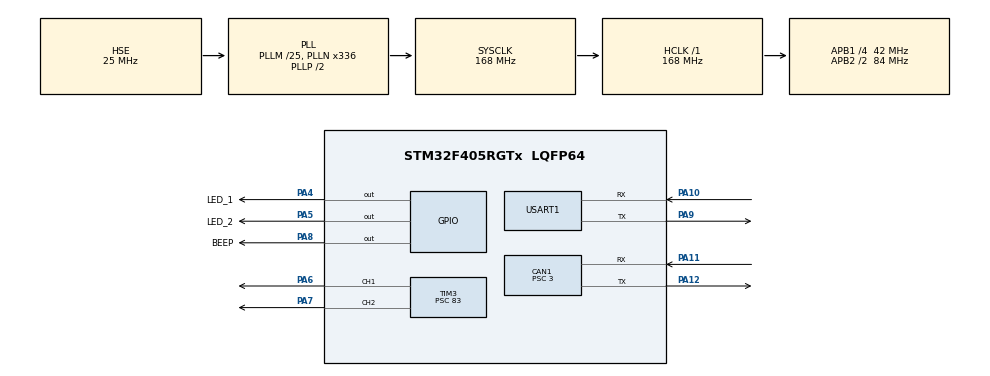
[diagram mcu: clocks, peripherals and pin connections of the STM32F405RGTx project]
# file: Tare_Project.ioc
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CAN1.ABOM=ENABLE
CAN1.AWUM=ENABLE
CAN1.BS1=CAN_BS1_9TQ
CAN1.BS2=CAN_BS2_4TQ
CAN1.CalculateBaudRate=1000000
CAN1.CalculateTimeBit=1000
CAN1.CalculateTimeQuantum=71.42857142857143
CAN1.NART=ENABLE
CAN1.Prescaler=3
Dma.Request0=USART1_RX
Dma.Request1=USART1_TX
Dma.USART1_RX.0.Direction=DMA_PERIPH_TO_MEMORY
Dma.USART1_RX.0.FIFOMode=DMA_FIFOMODE_DISABLE
Dma.USART1_RX.0.Instance=DMA2_Stream2
Dma.USART1_RX.0.MemDataAlignment=DMA_MDATAALIGN_BYTE
Dma.USART1_RX.0.MemInc=DMA_MINC_ENABLE
Dma.USART1_RX.0.Mode=DMA_NORMAL
Dma.USART1_RX.0.PeriphDataAlignment=DMA_PDATAALIGN_BYTE
Dma.USART1_RX.0.PeriphInc=DMA_PINC_DISABLE
Dma.USART1_RX.0.Priority=DMA_PRIORITY_LOW
Dma.USART1_TX.1.Direction=DMA_MEMORY_TO_PERIPH
Dma.USART1_TX.1.FIFOMode=DMA_FIFOMODE_DISABLE
Dma.USART1_TX.1.Instance=DMA2_Stream7
Dma.USART1_TX.1.MemDataAlignment=DMA_MDATAALIGN_BYTE
Dma.USART1_TX.1.MemInc=DMA_MINC_ENABLE
Dma.USART1_TX.1.Mode=DMA_NORMAL
Dma.USART1_TX.1.PeriphDataAlignment=DMA_PDATAALIGN_BYTE
Dma.USART1_TX.1.PeriphInc=DMA_PINC_DISABLE
Dma.USART1_TX.1.Priority=DMA_PRIORITY_LOW
FREERTOS.Tasks01=defaultTask,24,128,StartDefaultTask,Default,NULL,Dynamic,NULL,NULL;LEDTASK,8,128,Breath_LED,As weak,NULL,Dynamic,NULL,NULL;UARTTask,8,128,Data_update,As weak,NULL,Dynamic,NULL,NULL;FLOATTASK,8,128,Receivefloat,As weak,NULL,Dynamic,NULL,NULL;BEERTASK,8,128,Beep,As weak,NULL,Dynamic,NULL,NULL;NoiseTASK,8,128,Noise,As weak,NULL,Dynamic,NULL,NULL
Mcu.Family=STM32F4
Mcu.Name=STM32F405RGTx
Mcu.Package=LQFP64
NVIC.CAN1_RX0_IRQn=true\:5\:0\:false\:false\:true\:true\:true\:true\:true
NVIC.CAN1_RX1_IRQn=true\:5\:0\:false\:false\:true\:true\:true\:true\:true
NVIC.DMA2_Stream2_IRQn=true\:5\:0\:false\:false\:true\:true\:false\:true\:true
NVIC.DMA2_Stream7_IRQn=true\:5\:0\:false\:false\:true\:true\:false\:true\:true
NVIC.PriorityGroup=NVIC_PRIORITYGROUP_4
NVIC.TIM1_UP_TIM10_IRQn=true\:15\:0\:false\:false\:true\:false\:false\:true\:true
NVIC.TIM2_IRQn=true\:5\:0\:false\:false\:true\:true\:true\:true\:true
NVIC.TIM3_IRQn=true\:5\:0\:false\:false\:true\:true\:true\:true\:true
NVIC.TimeBase=TIM1_UP_TIM10_IRQn
NVIC.TimeBaseIP=TIM1
NVIC.USART1_IRQn=true\:5\:0\:false\:false\:true\:true\:false\:true\:true
PA10.Mode=Asynchronous
PA10.Signal=USART1_RX
PA11.Mode=CAN_Activate
PA11.Signal=CAN1_RX
PA12.GPIO_PuPd=GPIO_PULLDOWN
PA12.Mode=CAN_Activate
PA12.Signal=CAN1_TX
PA13.Mode=Serial_Wire
PA13.Signal=SYS_JTMS-SWDIO
PA14.Mode=Serial_Wire
PA14.Signal=SYS_JTCK-SWCLK
PA4.GPIO_Label=LED_1
PA4.GPIO_PuPd=GPIO_PULLDOWN
PA4.Signal=GPIO_Output
PA5.GPIO_Label=LED_2
PA5.GPIO_PuPd=GPIO_PULLDOWN
PA5.Signal=GPIO_Output
PA6.Signal=S_TIM3_CH1
PA7.Signal=S_TIM3_CH2
PA8.GPIO_Label=BEEP
PA8.GPIO_PuPd=GPIO_PULLDOWN
PA8.Signal=GPIO_Output
PA9.Mode=Asynchronous
PA9.Signal=USART1_TX
PC14-OSC32_IN.Mode=LSE-External-Oscillator
PC14-OSC32_IN.Signal=RCC_OSC32_IN
PC15-OSC32_OUT.Mode=LSE-External-Oscillator
PC15-OSC32_OUT.Signal=RCC_OSC32_OUT
PH0-OSC_IN.Mode=HSE-External-Oscillator
PH0-OSC_IN.Signal=RCC_OSC_IN
PH1-OSC_OUT.Mode=HSE-External-Oscillator
PH1-OSC_OUT.Signal=RCC_OSC_OUT
ProjectManager.HeapSize=0x200
ProjectManager.StackSize=0x400
ProjectManager.TargetToolchain=MDK-ARM V5.32
RCC.48MHZClocksFreq_Value=84000000
RCC.AHBFreq_Value=168000000
RCC.APB1CLKDivider=RCC_HCLK_DIV4
RCC.APB1Freq_Value=42000000
RCC.APB1TimFreq_Value=84000000
RCC.APB2CLKDivider=RCC_HCLK_DIV2
RCC.APB2Freq_Value=84000000
RCC.APB2TimFreq_Value=168000000
RCC.CortexFreq_Value=168000000
RCC.HCLKFreq_Value=168000000
RCC.HSE_VALUE=25000000
RCC.HSI_VALUE=16000000
RCC.PLLM=25
RCC.PLLN=336
RCC.PLLSourceVirtual=RCC_PLLSOURCE_HSE
RCC.SYSCLKFreq_VALUE=168000000
RCC.SYSCLKSource=RCC_SYSCLKSOURCE_PLLCLK
RCC.VCOOutputFreq_Value=336000000
SH.S_TIM3_CH1.0=TIM3_CH1,PWM Generation1 CH1
SH.S_TIM3_CH2.0=TIM3_CH2,PWM Generation2 CH2
TIM2.Period=1999
TIM2.Prescaler=83
TIM3.Channel-PWM\ Generation1\ CH1=TIM_CHANNEL_1
TIM3.Channel-PWM\ Generation2\ CH2=TIM_CHANNEL_2
TIM3.Period=999
TIM3.Prescaler=83
USART1.VirtualMode=VM_ASYNC
VP_FREERTOS_VS_CMSIS_V2.Mode=CMSIS_V2
VP_SYS_VS_tim1.Mode=TIM1
VP_TIM2_VS_ClockSourceINT.Mode=Internal
VP_TIM3_VS_ClockSourceINT.Mode=Internal
board=custom

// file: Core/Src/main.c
/* USER CODE BEGIN Header */
/**
  ******************************************************************************
  * @file           : main.c
  * @brief          : Main program body
  ******************************************************************************
  * @attention
  *
  * Copyright (c) 2026 STMicroelectronics.
  * All rights reserved.
  *
  * This software is licensed under terms that can be found in the LICENSE file
  * in the root directory of this software component.
  * If no LICENSE file comes with this software, it is provided AS-IS.
  *
  ******************************************************************************
  */
/* USER CODE END Header */
#include "main.h"
#include "cmsis_os.h"
#include "can.h"
#include "dma.h"
#include "tim.h"
#include "usart.h"
#include "gpio.h"
#include "UART_IQRhandler.h"
#include "led.h"

void SystemClock_Config(void);
void MX_FREERTOS_Init(void);

int main(void)
{

  /* MCU Configuration--------------------------------------------------------*/

  /* Reset of all peripherals, Initializes the Flash interface and the Systick. */
  HAL_Init();

  /* Configure the system clock */
  SystemClock_Config();

  /* Initialize all configured peripherals */
  MX_GPIO_Init();
  MX_DMA_Init();
  MX_TIM2_Init();
  MX_TIM3_Init();
  MX_USART1_UART_Init();
  MX_CAN1_Init();
  /* USER CODE BEGIN 2 */
  UART_Start_Receive();
  HAL_TIM_PWM_Start(&htim3,TIM_CHANNEL_1);
  HAL_TIM_PWM_Start(&htim3,TIM_CHANNEL_2);
  /* USER CODE END 2 */

  /* Init scheduler */
  osKernelInitialize();  /* Call init function for freertos objects (in cmsis_os2.c) */
  MX_FREERTOS_Init();

  /* Start scheduler */
  osKernelStart();

  /* We should never get here as control is now taken by the scheduler */

  /* Infinite loop */
  while (1)
  {

  }
}

void SystemClock_Config(void)
{
  RCC_OscInitTypeDef RCC_OscInitStruct = {0};
  RCC_ClkInitTypeDef RCC_ClkInitStruct = {0};

  /** Configure the main internal regulator output voltage
  */
  __HAL_RCC_PWR_CLK_ENABLE();
  __HAL_PWR_VOLTAGESCALING_CONFIG(PWR_REGULATOR_VOLTAGE_SCALE1);

  /** Initializes the RCC Oscillators according to the specified parameters
  * in the RCC_OscInitTypeDef structure.
  */
  RCC_OscInitStruct.OscillatorType = RCC_OSCILLATORTYPE_HSE;
  RCC_OscInitStruct.HSEState = RCC_HSE_ON;
  RCC_OscInitStruct.PLL.PLLState = RCC_PLL_ON;
  RCC_OscInitStruct.PLL.PLLSource = RCC_PLLSOURCE_HSE;
  RCC_OscInitStruct.PLL.PLLM = 25;
  RCC_OscInitStruct.PLL.PLLN = 336;
  RCC_OscInitStruct.PLL.PLLP = RCC_PLLP_DIV2;
  RCC_OscInitStruct.PLL.PLLQ = 4;
  if (HAL_RCC_OscConfig(&RCC_OscInitStruct) != HAL_OK)
  {
    Error_Handler();
  }

  /** Initializes the CPU, AHB and APB buses clocks
  */
  RCC_ClkInitStruct.ClockType = RCC_CLOCKTYPE_HCLK|RCC_CLOCKTYPE_SYSCLK
                              |RCC_CLOCKTYPE_PCLK1|RCC_CLOCKTYPE_PCLK2;
  RCC_ClkInitStruct.SYSCLKSource = RCC_SYSCLKSOURCE_PLLCLK;
  RCC_ClkInitStruct.AHBCLKDivider = RCC_SYSCLK_DIV1;
  RCC_ClkInitStruct.APB1CLKDivider = RCC_HCLK_DIV4;
  RCC_ClkInitStruct.APB2CLKDivider = RCC_HCLK_DIV2;

  if (HAL_RCC_ClockConfig(&RCC_ClkInitStruct, FLASH_LATENCY_5) != HAL_OK)
  {
    Error_Handler();
  }
}

void HAL_TIM_PeriodElapsedCallback(TIM_HandleTypeDef *htim)
{
  if (htim->Instance == TIM1)
  {
    HAL_IncTick();
	  ledflow();
  }
}

void Error_Handler(void)
{
  __disable_irq();
  while (1)
  {
  }
}

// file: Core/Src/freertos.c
/* USER CODE BEGIN Header */
/**
  ******************************************************************************
  * File Name          : freertos.c
  * Description        : Code for freertos applications
  ******************************************************************************
  * @attention
  *
  * Copyright (c) 2026 STMicroelectronics.
  * All rights reserved.
  *
  * This software is licensed under terms that can be found in the LICENSE file
  * in the root directory of this software component.
  * If no LICENSE file comes with this software, it is provided AS-IS.
  *
  ******************************************************************************
  */
/* USER CODE END Header */

#include "FreeRTOS.h"
#include "task.h"
#include "main.h"
#include "cmsis_os.h"

/* Definitions for defaultTask */
osThreadId_t defaultTaskHandle;
const osThreadAttr_t defaultTask_attributes = {
  .name = "defaultTask",
  .stack_size = 128 * 4,
  .priority = (osPriority_t) osPriorityNormal,
};
/* Definitions for LEDTASK */
osThreadId_t LEDTASKHandle;
const osThreadAttr_t LEDTASK_attributes = {
  .name = "LEDTASK",
  .stack_size = 128 * 4,
  .priority = (osPriority_t) osPriorityLow,
};
/* Definitions for UARTTask */
osThreadId_t UARTTaskHandle;
const osThreadAttr_t UARTTask_attributes = {
  .name = "UARTTask",
  .stack_size = 128 * 4,
  .priority = (osPriority_t) osPriorityLow,
};
/* Definitions for FLOATTASK */
osThreadId_t FLOATTASKHandle;
const osThreadAttr_t FLOATTASK_attributes = {
  .name = "FLOATTASK",
  .stack_size = 128 * 4,
  .priority = (osPriority_t) osPriorityLow,
};
/* Definitions for BEERTASK */
osThreadId_t BEERTASKHandle;
const osThreadAttr_t BEERTASK_attributes = {
  .name = "BEERTASK",
  .stack_size = 128 * 4,
  .priority = (osPriority_t) osPriorityLow,
};
/* Definitions for NoiseTASK */
osThreadId_t NoiseTASKHandle;
const osThreadAttr_t NoiseTASK_attributes = {
  .name = "NoiseTASK",
  .stack_size = 128 * 4,
  .priority = (osPriority_t) osPriorityLow,
};

void StartDefaultTask(void *argument);
void Breath_LED(void *argument);
void Data_update(void *argument);
void Receivefloat(void *argument);
void Beep(void *argument);
void Noise(void *argument);

void MX_FREERTOS_Init(void); /* (MISRA C 2004 rule 8.1) */

void MX_FREERTOS_Init(void) {

  /* Create the thread(s) */
  /* creation of defaultTask */
  defaultTaskHandle = osThreadNew(StartDefaultTask, NULL, &defaultTask_attributes);

  /* creation of LEDTASK */
  LEDTASKHandle = osThreadNew(Breath_LED, NULL, &LEDTASK_attributes);

  /* creation of UARTTask */
  UARTTaskHandle = osThreadNew(Data_update, NULL, &UARTTask_attributes);

  /* creation of FLOATTASK */
  FLOATTASKHandle = osThreadNew(Receivefloat, NULL, &FLOATTASK_attributes);

  /* creation of BEERTASK */
  BEERTASKHandle = osThreadNew(Beep, NULL, &BEERTASK_attributes);

  /* creation of NoiseTASK */
  NoiseTASKHandle = osThreadNew(Noise, NULL, &NoiseTASK_attributes);

}

void StartDefaultTask(void *argument)
{
  for(;;)
  {
    osDelay(1);
  }
}

__weak void Breath_LED(void *argument)
{
  for(;;)
  {
    osDelay(1);
  }
}

__weak void Data_update(void *argument)
{
  for(;;)
  {
    osDelay(1);
  }
}

__weak void Receivefloat(void *argument)
{
  for(;;)
  {
    osDelay(1);
  }
}

__weak void Beep(void *argument)
{
  for(;;)
  {
    osDelay(1);
  }
}

__weak void Noise(void *argument)
{
  for(;;)
  {
    osDelay(1);
  }
}
